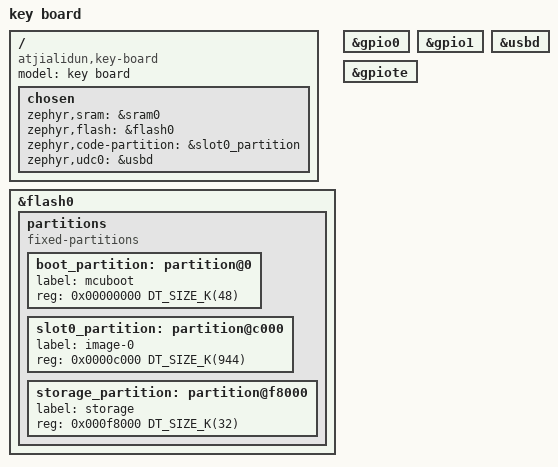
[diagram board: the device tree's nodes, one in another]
/dts-v1/;
#include <nordic/nrf52840_qiaa.dtsi>
#include "key_board-pinctrl.dtsi"

/ {
	model = "key board";
	compatible = "atjialidun,key-board";

	chosen {
		zephyr,sram = &sram0;
		zephyr,flash = &flash0;
		zephyr,code-partition = &slot0_partition;
	};
};

&flash0 {
	partitions {
		compatible = "fixed-partitions";
		#address-cells = <1>;
		#size-cells = <1>;

		boot_partition: partition@0 {
			label = "mcuboot";
			reg = <0x00000000 DT_SIZE_K(48)>;
		};

		slot0_partition: partition@c000 {
			label = "image-0";
			reg = <0x0000c000 DT_SIZE_K(944)>;
		};

		storage_partition: partition@f8000 {
			label = "storage";
			reg = <0x000f8000 DT_SIZE_K(32)>;
		};
	};
};

&gpio0 {
	status = "okay";
};

&gpio1 {
	status = "okay";
};

&gpiote {
	status = "okay";
};

/* 给现有的 usbd 节点追加一个 zephyr_udc0 的 label 别名 */
zephyr_udc0: &usbd {
    status = "okay";
};

/ {
    chosen {
        zephyr,udc0 = &usbd;
    };
};

&usbd {
    status = "okay";
};
